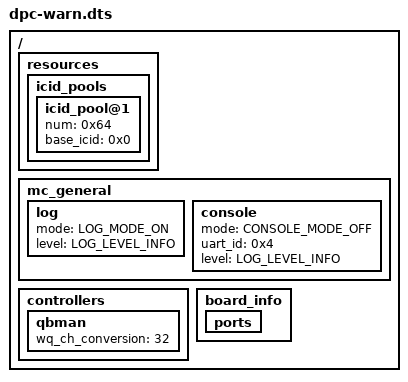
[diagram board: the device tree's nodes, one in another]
/dts-v1/;

/ {

	resources {

		icid_pools {

			icid_pool@1 {
				num = <0x64>;
				base_icid = <0x0>;
			};
		};
	};

	mc_general {

		log {
			mode = "LOG_MODE_ON";
			level = "LOG_LEVEL_INFO";
		};

		console {
			mode = "CONSOLE_MODE_OFF";
			uart_id = <0x4>;
			level = "LOG_LEVEL_INFO";
		};
	};

	controllers {

		qbman {
			/* Transform this number of 8-WQ channels into four times
			 * as many 2-WQ channels. This allows the creation of a
			 * larger number of DPCONs.
			 */
			wq_ch_conversion = <32>;
		};
	};

	board_info {

		ports {
		};
	};
};
